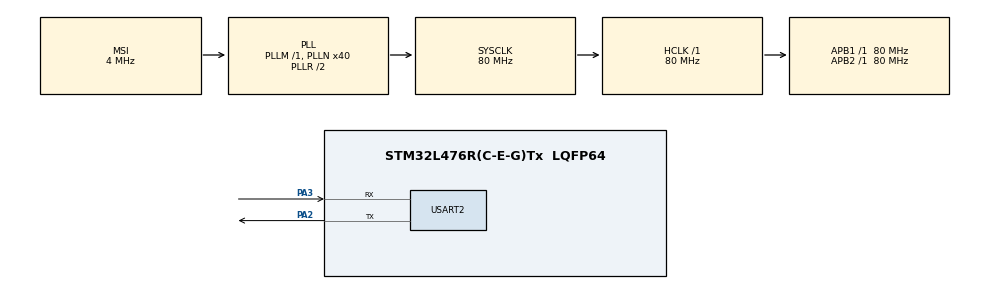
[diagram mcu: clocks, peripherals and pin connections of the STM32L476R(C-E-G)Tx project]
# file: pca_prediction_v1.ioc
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Mcu.Family=STM32L4
Mcu.Name=STM32L476R(C-E-G)Tx
Mcu.Package=LQFP64
NVIC.PriorityGroup=NVIC_PRIORITYGROUP_4
NVIC.USART2_IRQn=true\:0\:0\:false\:false\:true\:true\:true
PA2.Mode=Asynchronous
PA2.Signal=USART2_TX
PA3.Mode=Asynchronous
PA3.Signal=USART2_RX
ProjectManager.HeapSize=0x200
ProjectManager.StackSize=0x400
ProjectManager.TargetToolchain=STM32CubeIDE
RCC.AHBFreq_Value=80000000
RCC.APB1Freq_Value=80000000
RCC.APB1TimFreq_Value=80000000
RCC.APB2Freq_Value=80000000
RCC.APB2TimFreq_Value=80000000
RCC.CortexFreq_Value=80000000
RCC.HCLKFreq_Value=80000000
RCC.HSE_VALUE=8000000
RCC.HSI_VALUE=16000000
RCC.LSE_VALUE=32768
RCC.MSI_VALUE=4000000
RCC.PLLN=40
RCC.SYSCLKFreq_VALUE=80000000
RCC.SYSCLKSource=RCC_SYSCLKSOURCE_PLLCLK
RCC.VCOOutputFreq_Value=160000000
USART2.VirtualMode-Asynchronous=VM_ASYNC
board=custom

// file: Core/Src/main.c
/* USER CODE BEGIN Header */
/**
  ******************************************************************************
  * @file           : main.c
  * @brief          : Main program body
  ******************************************************************************
  * @attention
  *
  * <h2><center>&copy; Copyright (c) 2021 STMicroelectronics.
  * All rights reserved.</center></h2>
  *
  * This software component is licensed by ST under BSD 3-Clause license,
  * the "License"; You may not use this file except in compliance with the
  * License. You may obtain a copy of the License at:
  *                        opensource.org/licenses/BSD-3-Clause
  *
  ******************************************************************************
  */
/* USER CODE END Header */
#include "main.h"
#include <stdlib.h>
#include <stdio.h>
#include <string.h>
#include <stdint.h>

/* USER CODE BEGIN PV */
/*
 * UART2
 */
uint8_t myRxdata[ACC_LEN];
uint16_t acc_len = ACC_LEN;

/*
 * PCA PART
 */
int window;
uint16_t 	i,j,valid_window_count;
float32_t  	buff_in[(int16_t)INPUT_SIZE] = {0};
float32_t 	buff_reconst[(uint32_t)INPUT_SIZE];
float32_t 	buff_mse[(uint32_t)BUFF_OUTPUT_LEN];
float32_t 	mse;

uint16_t high_dim = HIGH_DIM;
uint16_t samples_num = SAMPLE_NUM;
uint16_t low_dim = K;
/* USER CODE END PV */

void SystemClock_Config(void);

int main(void)
{

  /* MCU Configuration--------------------------------------------------------*/

  /* Reset of all peripherals, Initializes the Flash interface and the Systick. */
  HAL_Init();

  /* Configure the system clock */
  SystemClock_Config();

  /* Initialize all configured peripherals */
  MX_GPIO_Init();
  MX_USART2_UART_Init();

  /* Infinite loop */
  while (1)
  {
      HAL_UART_Receive_IT(&huart2, myRxdata, acc_len);
	  if (window == FULL)
	  {
		  mse = pca(buff_in, buff_reconst); 		/* Perform PCA when window is full */
		  buff_mse[j] = mse;						/* keep MSE values for period of 15 minutes */
		  window = NFULL;
		  j++;
		  i = 0;
		  if (mse != 0) valid_window_count ++;		/* keep track of number of valid windows 	*/
		  if (j == BUFF_OUTPUT_LEN) j = 0 ;			/* reset at the end of 15 minutes			*/

	  	  }
  }
}

void SystemClock_Config(void)
{
  RCC_OscInitTypeDef RCC_OscInitStruct = {0};
  RCC_ClkInitTypeDef RCC_ClkInitStruct = {0};
  RCC_PeriphCLKInitTypeDef PeriphClkInit = {0};

  /** Initializes the RCC Oscillators according to the specified parameters
  * in the RCC_OscInitTypeDef structure.
  */
  RCC_OscInitStruct.OscillatorType = RCC_OSCILLATORTYPE_MSI;
  RCC_OscInitStruct.MSIState = RCC_MSI_ON;
  RCC_OscInitStruct.MSICalibrationValue = 0;
  RCC_OscInitStruct.MSIClockRange = RCC_MSIRANGE_6;
  RCC_OscInitStruct.PLL.PLLState = RCC_PLL_ON;
  RCC_OscInitStruct.PLL.PLLSource = RCC_PLLSOURCE_MSI;
  RCC_OscInitStruct.PLL.PLLM = 1;
  RCC_OscInitStruct.PLL.PLLN = 40;
  RCC_OscInitStruct.PLL.PLLP = RCC_PLLP_DIV7;
  RCC_OscInitStruct.PLL.PLLQ = RCC_PLLQ_DIV2;
  RCC_OscInitStruct.PLL.PLLR = RCC_PLLR_DIV2;
  if (HAL_RCC_OscConfig(&RCC_OscInitStruct) != HAL_OK)
  {
    Error_Handler();
  }
  /** Initializes the CPU, AHB and APB buses clocks
  */
  RCC_ClkInitStruct.ClockType = RCC_CLOCKTYPE_HCLK|RCC_CLOCKTYPE_SYSCLK
                              |RCC_CLOCKTYPE_PCLK1|RCC_CLOCKTYPE_PCLK2;
  RCC_ClkInitStruct.SYSCLKSource = RCC_SYSCLKSOURCE_PLLCLK;
  RCC_ClkInitStruct.AHBCLKDivider = RCC_SYSCLK_DIV1;
  RCC_ClkInitStruct.APB1CLKDivider = RCC_HCLK_DIV1;
  RCC_ClkInitStruct.APB2CLKDivider = RCC_HCLK_DIV1;

  if (HAL_RCC_ClockConfig(&RCC_ClkInitStruct, FLASH_LATENCY_4) != HAL_OK)
  {
    Error_Handler();
  }
  PeriphClkInit.PeriphClockSelection = RCC_PERIPHCLK_USART2;
  PeriphClkInit.Usart2ClockSelection = RCC_USART2CLKSOURCE_PCLK1;
  if (HAL_RCCEx_PeriphCLKConfig(&PeriphClkInit) != HAL_OK)
  {
    Error_Handler();
  }
  /** Configure the main internal regulator output voltage
  */
  if (HAL_PWREx_ControlVoltageScaling(PWR_REGULATOR_VOLTAGE_SCALE1) != HAL_OK)
  {
    Error_Handler();
  }
}

/* USER CODE BEGIN 4 */
void HAL_UART_RxCpltCallback(UART_HandleTypeDef *huart){

    UNUSED(huart);
	float32_t acceleration;
	acceleration = atof(myRxdata);
	buff_in[i] = acceleration;
	i ++;
			if (i == INPUT_SIZE){
						window = FULL;
				} // end if(i == HIGH_DIM)
}
/* USER CODE END 4 */

void Error_Handler(void)
{
  __disable_irq();
  while (1)
  {
  }
}

/************************ (C) COPYRIGHT STMicroelectronics *****END OF FILE****/
